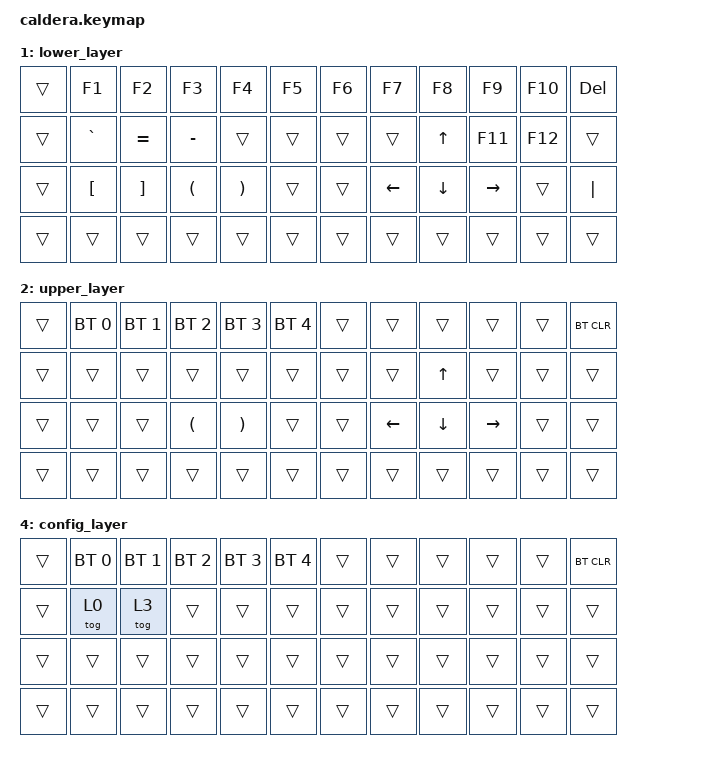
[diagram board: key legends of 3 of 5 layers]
#include <behaviors.dtsi>
#include <dt-bindings/zmk/bt.h>
#include <dt-bindings/zmk/keys.h>

/ {
    keymap {
        compatible = "zmk,keymap";

        default_layer {
            // ---------------------------------------------------------------------------------
            // |   `  |  1  |  2  |  3  |  4  |  5  |     |  6  |  7  |  8  |  9  |  0  | BKSP |
            // |  TAB |  Q  |  W  |  E  |  R  |  T  |     |  Y  |  U  |  I  |  O  |  P  |  \   |
            // | CAPS |  A  |  S  |  D  |  F  |  G  |     |  H  |  J  |  K  |  L  |  ;  |  ENT |
            // | SHFT |  Z  |  X  |  C  |  V  |  B  |     |  N  |  M  |  ,  |  .  |  /  | APOS |
            // | CTRL | ALT | GUI | SPC | SPC | SPC |     | SPC | LOW |LARW |DARW |UARW | RARW |

            bindings = <
&kp ESCAPE        &kp N1            &kp N2        &kp N3            &kp N4  &kp N5       &kp N6     &kp N7  &kp N8             &kp N9         &kp N0             &kp BSPC
&kp TAB           &kp Q             &kp W         &kp E             &kp R   &kp T        &kp Y      &kp U   &kp I              &kp O          &kp P              &kp ENTER
&kp LEFT_CONTROL  &kp A             &kp S         &kp D             &kp F   &kp G        &kp H      &kp J   &kp K              &kp L          &kp SEMI           &kp SINGLE_QUOTE
&kp LSHFT         &kp Z             &kp X         &kp C             &kp V   &kp B        &kp N      &kp M   &kp COMMA          &kp DOT        &kp FSLH           &kp RIGHT_SHIFT
&trans            &kp LEFT_CONTROL  &kp LEFT_ALT  &kp LEFT_COMMAND  &mo 1   &kp SPACE    &kp SPACE  &mo 2   &kp RIGHT_COMMAND  &kp RIGHT_ALT  &kp RIGHT_CONTROL  &tog 4
            >;
        };

        lower_layer {
            // ------------------------------------------------------------------------------------------------------------
            // |       |  BT1  |  BT2  |  BT3  |  BT4  |  BT5  |          |       |       |       |       |       | BTCLR |
            // |       |       |       |       |       |       |          |       |       |       |       |       |       |
            // |       |       |       | LPAR  | RPAR  |       |          |       | LBKT  | RBKT  |       |       |       |
            // |       |       |       |       |       |       |          |       |       |       |       |       |       |

            bindings = <
&trans  &kp F1            &kp F2             &kp F3     &kp F4    &kp F5    &kp F6  &kp F7    &kp F8        &kp F9     &kp F10  &kp DELETE
&trans  &kp GRAVE         &kp EQUAL          &kp MINUS  &trans    &trans    &trans  &trans    &kp UP_ARROW  &kp F11    &kp F12  &trans
&trans  &kp LEFT_BRACKET  &kp RIGHT_BRACKET  &kp LPAR   &kp RPAR  &trans    &trans  &kp LEFT  &kp DOWN      &kp RIGHT  &trans   &kp PIPE
&trans  &trans            &trans             &trans     &trans    &trans    &trans  &trans    &trans        &trans     &trans   &trans
            >;
        };

        upper_layer {
            bindings = <
&trans  &bt BT_SEL 0  &bt BT_SEL 1  &bt BT_SEL 2  &bt BT_SEL 3  &bt BT_SEL 4    &trans  &trans    &trans        &trans     &trans  &bt BT_CLR
&trans  &trans        &trans        &trans        &trans        &trans          &trans  &trans    &kp UP_ARROW  &trans     &trans  &trans
&trans  &trans        &trans        &kp LPAR      &kp RPAR      &trans          &trans  &kp LEFT  &kp DOWN      &kp RIGHT  &trans  &trans
&trans  &trans        &trans        &trans        &trans        &trans          &trans  &trans    &trans        &trans     &trans  &trans
            >;
        };

        windows_layer {
            bindings = <
&kp ESCAPE        &kp N1            &kp N2        &kp N3        &kp N4  &kp N5       &kp N6     &kp N7  &kp N8         &kp N9         &kp N0             &kp BSPC
&kp TAB           &kp Q             &kp W         &kp E         &kp R   &kp T        &kp Y      &kp U   &kp I          &kp O          &kp P              &kp ENTER
&kp LEFT_CONTROL  &kp A             &kp S         &kp D         &kp F   &kp G        &kp H      &kp J   &kp K          &kp L          &kp SEMI           &kp SINGLE_QUOTE
&kp LSHFT         &kp Z             &kp X         &kp C         &kp V   &kp B        &kp N      &kp M   &kp COMMA      &kp DOT        &kp FSLH           &kp RIGHT_SHIFT
&trans            &kp LEFT_CONTROL  &kp LEFT_GUI  &kp LEFT_ALT  &mo 1   &kp SPACE    &kp SPACE  &mo 2   &kp RIGHT_ALT  &kp RIGHT_GUI  &kp RIGHT_CONTROL  &tog 4
            >;
        };

        config_layer {
            bindings = <
&trans  &bt BT_SEL 0  &bt BT_SEL 1  &bt BT_SEL 2  &bt BT_SEL 3  &bt BT_SEL 4    &trans  &trans  &trans  &trans  &trans  &bt BT_CLR
&trans  &tog 0        &tog 3        &trans        &trans        &trans          &trans  &trans  &trans  &trans  &trans  &trans
&trans  &trans        &trans        &trans        &trans        &trans          &trans  &trans  &trans  &trans  &trans  &trans
&trans  &trans        &trans        &trans        &trans        &trans          &trans  &trans  &trans  &trans  &trans  &trans
            >;
        };
    };
};
